# A31M22x register map
Vendor: ABOV Semiconductor Co., Ltd.; File version: 1.0
CPU: CM0PLUS r0p1, little endian, no MPU, no FPU, VTOR, 2 interrupt priority bits
Registers are 32-bit, read-write, reset 0x0 unless marked. A register's access mark holds for its fields unless they carry their own. Offsets are from the block's base; [hi:lo] are bit positions; {n}, {i} and the like mark numbered series.

## SPI — Serial Peripheral Interface Bus
Base 0x40009000
0x00 TDR wo — SPI Transmit Data Register
  [16:0] TDR — Transmit Data Bit
0x00 RDR ro — SPI Received Data Register
  [16:0] RDR — Received Data Bit
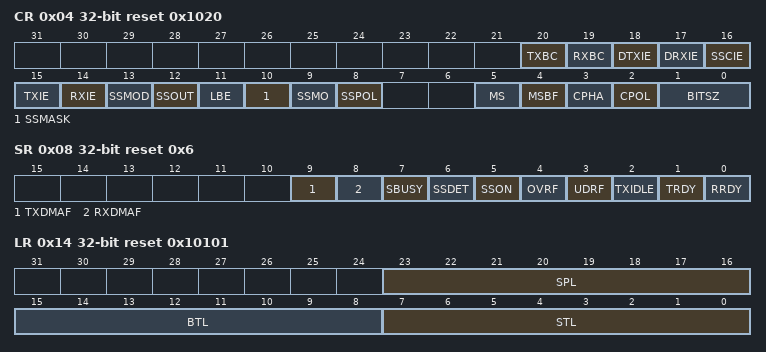
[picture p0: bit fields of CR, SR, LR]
0x04 CR reset 0x1020 — SPI Control Register
  [20] TXBC — Tx Buffer Clear Bit
  [19] RXBC — Rx Buffer Clear Bit
  [18] DTXIE — DMA Tx Complete Interrupt Enable Bit
  [17] DRXIE — DMA Rx Complete Interrupt Enable Bit
  [16] SSCIE — SS Edge Changed Interrupt Enable Bit
  [15] TXIE — Transmit Interrupt Enable Bit
  [14] RXIE — Received Interrupt Enable Bit
  [13] SSMOD — SS Auto/Manual Output selection Bit in Master Mode
  [12] SSOUT — SS Output Signal Control Bit
  [11] LBE — Loop-back Mode selection Bit in Master Mode
  [10] SSMASK — SS Signal Masking in Slave Mode
  [9] SSMO — SS Output Signal selection Bit
  [8] SSPOL — SS Signal Polarity selection Bit
  [5] MS — Master/Slave selection Bit
  [4] MSBF — MSB/LSB Transmit Advance selection Bit
  [3] CPHA — SPI Clock Phase Bit
  [2] CPOL — SPI Clock Polarity Bit
  [1:0] BITSZ — Transmit/Receive Bit Size selection Bit
    0=8_BIT (Size is 8 bit); 1=9_BIT (Size is 9 bit); 2=16_BIT (Size is 16 bit); 3=17_BIT (Size is 17 bit)
0x08 SR reset 0x6 — SPI Status Register
  [9] TXDMAF — DMA Transmit Operation Complete Flag
  [8] RXDMAF — DMA Received Operation Complete Flag
  [7] SBUSY ro — Transmit/Received Operating Flag
  [6] SSDET — SS Signal Rising or Falling Edge Detected Flag
  [5] SSON — SS Signal Status Flag
  [4] OVRF — Received Overrun Error Flag
  [3] UDRF — Transmit Underrun Error Flag
  [2] TXIDLE ro — Transmit Operating Flag
  [1] TRDY ro — Transmit Buffer Empty Flag
  [0] RRDY ro — Received Buffer Empty Flag
0x0C BR reset 0xFFFF — SPI Baud Rate Register
  [15:0] BR — Baud Rate Setting Bit
0x10 EN — SPI Enable Register
  [0] ENABLE — SPI Enable Bit
0x14 LR reset 0x10101 — SPI Delay Length Register
  [23:16] SPL — SPI STOP Length Value Bit
  [15:8] BTL — SPI Burst Length Value Bit
  [7:0] STL — SPI Start Length Value Bit

## I2C — Inter-Integrated Circuit
Base 0x4000A000
0x00 DR reset 0xFF — I2C Data Register
  [7:0] ICDR — The I2CDR Transmit buffer and Receive buffer share the same I/O address with this DATA register. The Transmit Data Buffer is the destination for data written to the I2CDR register. Reading the I2CDR register returns the contents of the Receive Buffer.
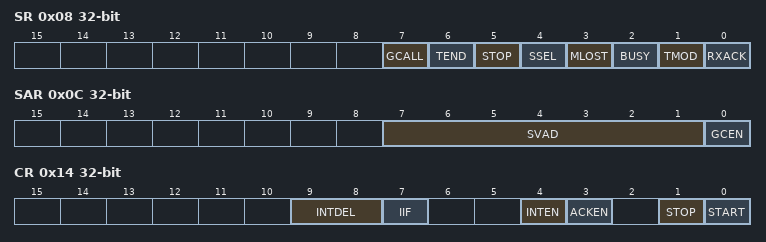
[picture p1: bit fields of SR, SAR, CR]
0x08 SR — I2C Status Register
  [7] GCALL — This bit has different meaning depending on whether I2C is master or slave. When I2C is a master, this bit represents whether it received AACK (address ACK) from slave.
  [6] TEND — This bit is set when 1-byte of data is transferred completely.
  [5] STOP — This bit is set when a STOP condition is detected.
  [4] SSEL — This bit is set when I2C is addressed by other master.
  [3] MLOST — This bit represents the result of bus arbitration in master mode.
  [2] BUSY ro — This bit reflects bus status.
  [1] TMOD ro — This bit is used to indicate whether I2C is transmitter or receiver.
  [0] RXACK — This bit shows the state of ACK signal.
0x0C SAR — I2C Slave Address Register
  [7:1] SVAD — These bits configure the slave address in slave mode.
  [0] GCEN — This bit decides whether I2C allows general call address 0 or not in I2C slave mode.
0x14 CR — I2C Control Register
  [9:8] INTDEL — between Address and Transmit data delay
    0=1_ICnSCLL (Delay = 1*ICnSCLL); 1=2_ICnSCLL (Delay = 2*ICnSCLL); 2=4_ICnSCLL (Delay = 4*ICnSCLL); 3=8_ICnSCLL (Delay = 8*ICnSCLL)
  [7] IIF ro — I2C Interrupt Flag bit. This bit is cleared when write any values in the I2CST register.
  [4] INTEN — Interrupt Enable bit
  [3] ACKEN — received mode ACK allow bit
  [1] STOP — STOP Condition Generation When I2C is master.
  [0] START — START Condition Generation When I2C is master.
0x18 SCLL reset 0xFFFF — I2C SCL Low Duration Register
  [15:0] SCLL — This register defines the low period of SCL in master mode. The base clock is PCLK and the period is calculated by the formula: tPCLK X (4 X I2CSCLR + 2) where tPCLK is the period of PCLK.
0x1C SCLH reset 0xFFFF — I2C SCL High Duration Register
  [15:0] SCLH — SCLH Value
0x20 SDH reset 0x7FFF — I2C SDA Hold Register
  [14:0] SDH — SDH Value

## OPAMP
Base 0x4000B300
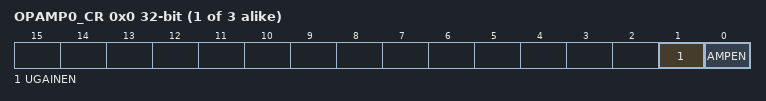
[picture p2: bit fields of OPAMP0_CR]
{0x0+4i} OPAMP{i}_CR (i=0..2) — OPAMP {i} Control Register
  [1] UGAINEN — Unit gain enable bit
  [0] AMPEN — Opamp enable bit

## CMP — Comparator
Base 0x4000B380
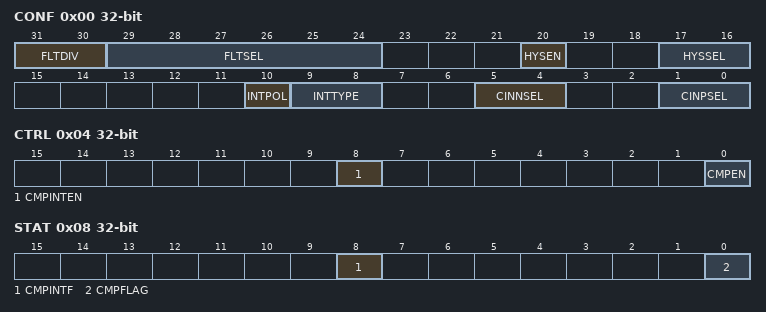
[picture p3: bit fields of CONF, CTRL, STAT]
0x00 CONF — Comparator Configure Register
  [31:30] FLTDIV — Digital Filter Clock Divider bit
  [29:24] FLTSEL — Digital Filter Counter bit
  [20] HYSEN — Hysteresis Enable Bit
    0=Disable; 1=Enable
  [17:16] HYSSEL — Hysteresis Selection Bit
    0=10mV Hysteresis; 1=20mV Hysteresis; 2=30mV Hysteresis; 3=40mV Hysteresis
  [10] INTPOL — Interrupt Polarity Selection Bit
    0=Low (Low(Falling)); 1=High(Rising)
  [9:8] INTTYPE — Interrupt Type Selection Bit
    0=Disable; 1=Level; 2=Single_Edge; 3=Both_Edge
  [5:4] CINNSEL — Comparator Reference (Input-) Selection Bit
    0=CMP0R (CMP0R pin input); 1=Vref (Reference voltage (1V)); 2=Ground; 3=Ground
  [1:0] CINPSEL — Comparator Source (Input+) Selection Bit
    0=CPA (CPA pin input); 1=CPB (CPB pin input); 2=CPC (CPC pin input); 3=Ground
0x04 CTRL — Comparator Control Register
  [8] CMPINTEN — Comparator Interrupt Enable Bit
    0=Disable comparator interrupt; 1=Enable comparator interrupt
  [0] CMPEN — Comparator Enable Bit
    0=Disable compartor; 1=Enable compartor
0x08 STAT — Comparator Status Register
  [8] CMPINTF — Comparator Interrupt Flag Bit
  [0] CMPFLAG ro — Comparator Output Status
0x30 DBCR — Comparator Debounce Control Register
  [0] DBEN wo — Comparator Output Pin Debounce Filter Enable Bit

## CRC — CYCLIC REDUNDANCY CHECK AND CHECKSUM
Base 0x41002000
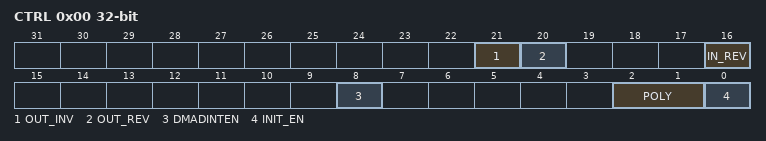
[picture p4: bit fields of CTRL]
0x00 CTRL — CRC Control Register
  [21] OUT_INV — CRC Output Data Inversion Enable bit
  [20] OUT_REV — CRC Output Data Reverse Enable Bit
  [16] IN_REV — Input Data Reverse Mode selection Bit
  [8] DMADINTEN — DMA Done Interrupt Enable Bit
  [2:1] POLY — Polynomal selection Bit
    0=CRC32 (CRC32 (0x04C1_1DB7)); 1=CRC16_USB (CRC16_USB (0x8005)); 2=CRC16_CCITT (CRC16_CCITT (0x1021)); 3=CRC8_CCITT (CRC8_CCITT (0x07))
  [0] INIT_EN wo — CRC Init Register Apply Bit
0x04 INIT — CRC Initial Data Register
  [31:0] INIT — CRC Initial Value
0x08 IDR wo — CRC Input Data Register
  [31:0] IDR — CRC Input Data Bit
0x08 ODR ro — CRC Output Data Register
  [31:0] ODR — CRC Output Data Bit
0x0C STAT — CRC Status Register
  [8] DMADINT — DMA Done Interrupt Flag Bit
